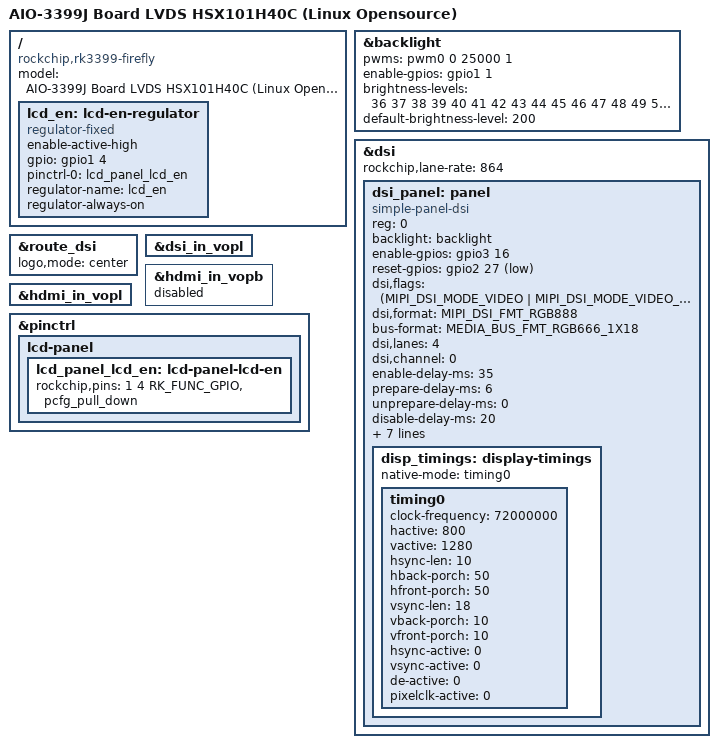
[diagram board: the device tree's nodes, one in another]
/*
 * Copyright (c) 2016 Fuzhou Rockchip Electronics Co., Ltd
 *
 * This file is dual-licensed: you can use it either under the terms
 * of the GPL or the X11 license, at your option. Note that this dual
 * licensing only applies to this file, and not this project as a
 * whole.
 *
 *  a) This file is free software; you can redistribute it and/or
 *     modify it under the terms of the GNU General Public License as
 *     published by the Free Software Foundation; either version 2 of the
 *     License, or (at your option) any later version.
 *
 *     This file is distributed in the hope that it will be useful,
 *     but WITHOUT ANY WARRANTY; without even the implied warranty of
 *     MERCHANTABILITY or FITNESS FOR A PARTICULAR PURPOSE.  See the
 *     GNU General Public License for more details.
 *
 * Or, alternatively,
 *     restriction, including without limitation the rights to use,
 *     copy, modify, merge, publish, distribute, sublicense, and/or
 *     sell copies of the Software, and to permit persons to whom the
 *     Software is furnished to do so, subject to the following
 *     conditions:
 *
 *     The above copyright notice and this permission notice shall be
 *     included in all copies or substantial portions of the Software.
 *
 *     THE SOFTWARE IS PROVIDED "AS IS", WITHOUT WARRANTY OF ANY KIND,
 *     EXPRESS OR IMPLIED, INCLUDING BUT NOT LIMITED TO THE WARRANTIES
 *     OF MERCHANTABILITY, FITNESS FOR A PARTICULAR PURPOSE AND
 *     NONINFRINGEMENT. IN NO EVENT SHALL THE AUTHORS OR COPYRIGHT
 *     HOLDERS BE LIABLE FOR ANY CLAIM, DAMAGES OR OTHER LIABILITY,
 *     WHETHER IN AN ACTION OF CONTRACT, TORT OR OTHERWISE, ARISING
 *     FROM, OUT OF OR IN CONNECTION WITH THE SOFTWARE OR THE USE OR
 *     OTHER DEALINGS IN THE SOFTWARE.
 */

/dts-v1/;

#include "rk3399-firefly-aio.dtsi"
#include <dt-bindings/display/media-bus-format.h>

/ {
	model = "AIO-3399J Board LVDS HSX101H40C (Linux Opensource)";
	compatible = "rockchip,rk3399-firefly", "rockchip,rk3399";

	lcd_en:lcd-en-regulator {
		compatible = "regulator-fixed";
		enable-active-high;
		gpio = <&gpio1 4 GPIO_ACTIVE_HIGH>;
		pinctrl-names = "default";
		pinctrl-0 = <&lcd_panel_lcd_en>;
		regulator-name = "lcd_en";
		regulator-always-on;
	};
};

&backlight {
	status = "okay";
	pwms = <&pwm0 0 25000 1>;
	enable-gpios = <&gpio1 1 GPIO_ACTIVE_HIGH>;
	brightness-levels = </*
		  0   1   2   3   4   5   6   7
		  8   9  10  11  12  13  14  15
		 16  17  18  19  20  21  22  23
		 24  25  26  27  28  29  30  31
		 32  33  34  35*/36  37  38  39
		 40  41  42  43  44  45  46  47
		 48  49  50  51  52  53  54  55
		 56  57  58  59  60  61  62  63
		 64  65  66  67  68  69  70  71
		 72  73  74  75  76  77  78  79
		 80  81  82  83  84  85  86  87
		 88  89  90  91  92  93  94  95
		 96  97  98  99 100 101 102 103
		104 105 106 107 108 109 110 111
		112 113 114 115 116 117 118 119
		120 121 122 123 124 125 126 127
		128 129 130 131 132 133 134 135
		136 137 138 139 140 141 142 143
		144 145 146 147 148 149 150 151
		152 153 154 155 156 157 158 159
		160 161 162 163 164 165 166 167
		168 169 170 171 172 173 174 175
		176 177 178 179 180 181 182 183
		184 185 186 187 188 189 190 191
		192 193 194 195 196 197 198 199
		200 201 202 203 204 205 206 207
		208 209 210 211 212 213 214 215
		216 217 218 219 220 221 222 223
		224 225 226 227 228 229 230 231
		232 233 234 235 236 237 238 239
		240 241 242 243 244 245 246 247
		248 249 250 251 252 253 254 255>;
	default-brightness-level = <200>;
};

&dsi {
	status = "okay";
	rockchip,lane-rate = <864>;  //lvds_clock*6*2
	dsi_panel: panel {
		compatible ="simple-panel-dsi";
		reg = <0>;
		backlight = <&backlight>;
		enable-gpios = <&gpio3 16 GPIO_ACTIVE_HIGH>;
		reset-gpios = <&gpio2 27 GPIO_ACTIVE_LOW>;
		dsi,flags = <(MIPI_DSI_MODE_VIDEO | MIPI_DSI_MODE_VIDEO_BURST | MIPI_DSI_MODE_LPM | MIPI_DSI_MODE_EOT_PACKET)>;
		dsi,format = <MIPI_DSI_FMT_RGB888>;
		bus-format = <MEDIA_BUS_FMT_RGB666_1X18>;
		dsi,lanes = <4>;
		dsi,channel = <0>;
		enable-delay-ms = <35>;
		prepare-delay-ms = <6>;
		unprepare-delay-ms = <0>;
		disable-delay-ms = <20>;
		size,width = <120>;
		size,height = <170>;
		power-supply = <&lcd_en>;
		status = "okay";

		panel-init-sequence = [
			29 02 06 3C 01 09 00 07 00
			29 02 06 14 01 06 00 00 00
			29 02 06 64 01 0B 00 00 00
			29 02 06 68 01 0B 00 00 00
			29 02 06 6C 01 0B 00 00 00
			29 02 06 70 01 0B 00 00 00
			29 02 06 34 01 1F 00 00 00
			29 02 06 10 02 1F 00 00 00
			29 02 06 04 01 01 00 00 00
			29 02 06 04 02 01 00 00 00
			29 02 06 50 04 30 01 F0 03
			29 02 06 54 04 0A 00 32 00   //hsync_len = 0x0A    hback_porch =0x32
			29 02 06 58 04 20 03 32 00   //hactive   = 0x320   hfront_porch=0x32
			29 02 06 5C 04 12 00 0A 00   //vsync_len = 0x12    vback_porch =0x0A
			29 02 06 60 04 00 05 0A 00   //vactive   = 0x500   vfront_porch=0x0A
			29 02 06 64 04 01 00 00 00
			29 02 06 A0 04 06 80 44 00
			29 02 06 A0 04 06 80 04 00
			29 02 06 04 05 04 00 00 00
			29 02 06 80 04 00 01 02 03
			29 02 06 84 04 04 07 05 08
			29 02 06 88 04 09 0A 0E 0F
			29 02 06 8C 04 0B 0C 0D 10
			29 02 06 90 04 16 17 11 12
			29 02 06 94 04 13 14 15 1B
			29 02 06 98 04 18 19 1A 06
			29 02 06 9C 04 31 04 00 00
		];

		panel-exit-sequence = [
			05 05 01 28
			05 78 01 10
		];

		disp_timings: display-timings {
			native-mode = <&timing0>;
			timing0: timing0 {
				clock-frequency = <72000000>; //@60
				hactive = <800>;
				vactive = <1280>;
				hsync-len = <10>;
				hback-porch = <50>;
				hfront-porch = <50>;
				vsync-len = <18>;
				vback-porch = <10>;
				vfront-porch = <10>;
				hsync-active = <0>;
				vsync-active = <0>;
				de-active = <0>;
				pixelclk-active = <0>;
			};
		};
	};
};

&route_dsi {
	status = "okay";
	logo,mode = "center";
};

&dsi_in_vopl {
	status = "okay";
};

&hdmi_in_vopb {
	status = "disabled";
};

&hdmi_in_vopl {
	status = "okay";
};

&pinctrl {
	lcd-panel {
		lcd_panel_lcd_en:lcd-panel-lcd-en {
			rockchip,pins = <1 4 RK_FUNC_GPIO &pcfg_pull_down>;
		};
	};
};
